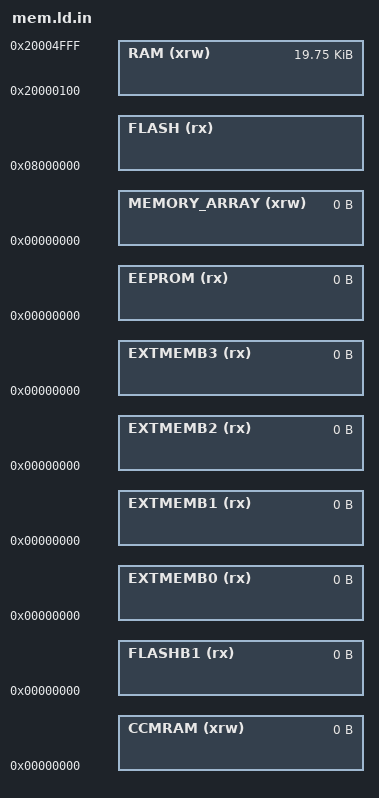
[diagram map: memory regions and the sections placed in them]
/*
 * Memory map of the bootloader on the STM32F103x8/xB. CMake makes mem.ld
 * from this file (configure_file()).
 *
 * FLASH: the bootloader area, @VERSALOON_BOOTLOADER_AREA_SIZE@ bytes at
 * 0x08000000. The application starts behind it. The link fails when the
 * bootloader does not fit in the area.
 *
 * RAM: 20 KB at 0x20000000. The first 0x100 bytes stay free for the copy
 * of the vector table that Interrupt::connectHandler() of system-stm32
 * makes at SRAM_BASE. The bootloader does not use interrupts, but
 * sections.ld requires the free RAM.
 */

MEMORY
{
  RAM (xrw) : ORIGIN = 0x20000100, LENGTH = 20K-0x100
  FLASH (rx) : ORIGIN = 0x08000000, LENGTH = @VERSALOON_BOOTLOADER_AREA_SIZE@
  CCMRAM (xrw) : ORIGIN = 0x00000000, LENGTH = 0
  FLASHB1 (rx) : ORIGIN = 0x00000000, LENGTH = 0
  EXTMEMB0 (rx) : ORIGIN = 0x00000000, LENGTH = 0
  EXTMEMB1 (rx) : ORIGIN = 0x00000000, LENGTH = 0
  EXTMEMB2 (rx) : ORIGIN = 0x00000000, LENGTH = 0
  EXTMEMB3 (rx) : ORIGIN = 0x00000000, LENGTH = 0
  EEPROM (rx) : ORIGIN = 0x00000000, LENGTH = 0
  MEMORY_ARRAY (xrw) : ORIGIN = 0x00000000, LENGTH = 0
}
